# MCU_M4FSS0_ECC_AGGR_0_ECC_AGGR register map
Vendor: Texas Instruments
Peripheral module from a debugger description file (folder am243x).
Registers are 32-bit, access not given, reset 0x0 unless marked. A register's access mark holds for its fields unless they carry their own. Offsets are as the file gives them; lines under a group give offsets from that group; [hi:lo] are bit positions; {n}, {i} and the like mark numbered series; 'fields as' and 'values as' point back to an identical list; <NAME> marks a mode.

## MCU_M4FSS0_ECC_AGGR_0_ECC_AGGR
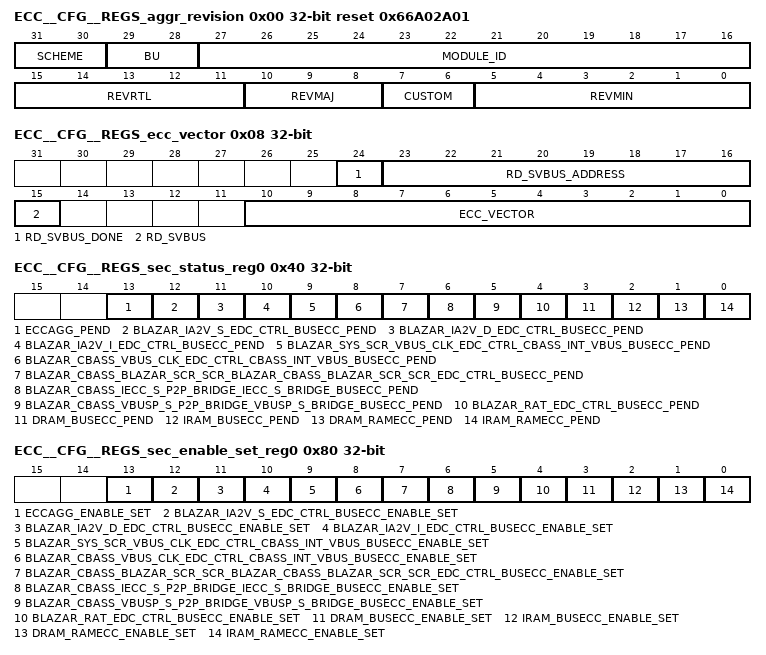
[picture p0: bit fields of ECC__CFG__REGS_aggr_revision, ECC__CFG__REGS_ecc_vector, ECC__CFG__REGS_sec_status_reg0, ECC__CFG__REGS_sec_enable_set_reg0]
0x00 ECC__CFG__REGS_aggr_revision ro reset 0x66A02A01 — Revision parameters
  [31:30] SCHEME
  [29:28] BU
  [27:16] MODULE_ID
  [15:11] REVRTL — RTL version
  [10:8] REVMAJ — Major version
  [7:6] CUSTOM — Custom version
  [5:0] REVMIN — Minor version
0x08 ECC__CFG__REGS_ecc_vector — ECC Vector Register
  [24] RD_SVBUS_DONE — Status to indicate if read on serial VBUS is complete, write of any value will clear this bit. (access R/W1TC)
  [23:16] RD_SVBUS_ADDRESS rw — Read address
  [15] RD_SVBUS — Write 1 to trigger a read on the serial VBUS (access R/W1TS)
  [10:0] ECC_VECTOR rw — Value written to select the corresponding ECC RAM for control or status
0x0C ECC__CFG__REGS_misc_status ro reset 0xE — Misc Status
  [10:0] NUM_RAMS — Indicates the number of RAMS serviced by the ECC aggregator
0x10 ECC__CFG__REGS_reserved_svbus rw — Reference other documents that contain the ECC RAM wrapper and EDC controller serial vbus register sets.
  [31:0] DATA — Serial VBUS register data
0x3C ECC__CFG__REGS_sec_eoi_reg — EOI Register
  [0] EOI_WR — EOI Register (access R/W1TS)
0x40 ECC__CFG__REGS_sec_status_reg0 — Interrupt Status Register 0
  [13] ECCAGG_PEND — Interrupt Pending Status for eccagg_pend (access R/W1TS)
  [12] BLAZAR_IA2V_S_EDC_CTRL_BUSECC_PEND — Interrupt Pending Status for blazar_Ia2v_s_edc_ctrl_busecc_pend (access R/W1TS)
  [11] BLAZAR_IA2V_D_EDC_CTRL_BUSECC_PEND — Interrupt Pending Status for blazar_Ia2v_d_edc_ctrl_busecc_pend (access R/W1TS)
  [10] BLAZAR_IA2V_I_EDC_CTRL_BUSECC_PEND — Interrupt Pending Status for blazar_Ia2v_i_edc_ctrl_busecc_pend (access R/W1TS)
  [9] BLAZAR_SYS_SCR_VBUS_CLK_EDC_CTRL_CBASS_INT_VBUS_BUSECC_PEND — Interrupt Pending Status for blazar_sys_scr_vbus_clk_edc_ctrl_cbass_int_vbus_busecc_pend (access R/W1TS)
  [8] BLAZAR_CBASS_VBUS_CLK_EDC_CTRL_CBASS_INT_VBUS_BUSECC_PEND — Interrupt Pending Status for blazar_cbass_vbus_clk_edc_ctrl_cbass_int_vbus_busecc_pend (access R/W1TS)
  [7] BLAZAR_CBASS_BLAZAR_SCR_SCR_BLAZAR_CBASS_BLAZAR_SCR_SCR_EDC_CTRL_BUSECC_PEND — Interrupt Pending Status for blazar_cbass_blazar_scr_scr_blazar_cbass_blazar_scr_scr_edc_ctrl_busecc_pend (access R/W1TS)
  [6] BLAZAR_CBASS_IECC_S_P2P_BRIDGE_IECC_S_BRIDGE_BUSECC_PEND — Interrupt Pending Status for blazar_cbass_Iecc_s_p2p_bridge_Iecc_s_bridge_busecc_pend (access R/W1TS)
  [5] BLAZAR_CBASS_VBUSP_S_P2P_BRIDGE_VBUSP_S_BRIDGE_BUSECC_PEND — Interrupt Pending Status for blazar_cbass_vbusp_s_p2p_bridge_vbusp_s_bridge_busecc_pend (access R/W1TS)
  [4] BLAZAR_RAT_EDC_CTRL_BUSECC_PEND — Interrupt Pending Status for blazar_rat_edc_ctrl_busecc_pend (access R/W1TS)
  [3] DRAM_BUSECC_PEND — Interrupt Pending Status for dram_busecc_pend (access R/W1TS)
  [2] IRAM_BUSECC_PEND — Interrupt Pending Status for iram_busecc_pend (access R/W1TS)
  [1] DRAM_RAMECC_PEND — Interrupt Pending Status for dram_ramecc_pend (access R/W1TS)
  [0] IRAM_RAMECC_PEND — Interrupt Pending Status for iram_ramecc_pend (access R/W1TS)
0x80 ECC__CFG__REGS_sec_enable_set_reg0 — Interrupt Enable Set Register 0
  [13] ECCAGG_ENABLE_SET — Interrupt Enable Set Register for eccagg_pend (access R/W1TS)
  [12] BLAZAR_IA2V_S_EDC_CTRL_BUSECC_ENABLE_SET — Interrupt Enable Set Register for blazar_Ia2v_s_edc_ctrl_busecc_pend (access R/W1TS)
  [11] BLAZAR_IA2V_D_EDC_CTRL_BUSECC_ENABLE_SET — Interrupt Enable Set Register for blazar_Ia2v_d_edc_ctrl_busecc_pend (access R/W1TS)
  [10] BLAZAR_IA2V_I_EDC_CTRL_BUSECC_ENABLE_SET — Interrupt Enable Set Register for blazar_Ia2v_i_edc_ctrl_busecc_pend (access R/W1TS)
  [9] BLAZAR_SYS_SCR_VBUS_CLK_EDC_CTRL_CBASS_INT_VBUS_BUSECC_ENABLE_SET — Interrupt Enable Set Register for blazar_sys_scr_vbus_clk_edc_ctrl_cbass_int_vbus_busecc_pend (access R/W1TS)
  [8] BLAZAR_CBASS_VBUS_CLK_EDC_CTRL_CBASS_INT_VBUS_BUSECC_ENABLE_SET — Interrupt Enable Set Register for blazar_cbass_vbus_clk_edc_ctrl_cbass_int_vbus_busecc_pend (access R/W1TS)
  [7] BLAZAR_CBASS_BLAZAR_SCR_SCR_BLAZAR_CBASS_BLAZAR_SCR_SCR_EDC_CTRL_BUSECC_ENABLE_SET — Interrupt Enable Set Register for blazar_cbass_blazar_scr_scr_blazar_cbass_blazar_scr_scr_edc_ctrl_busecc_pend (access R/W1TS)
  [6] BLAZAR_CBASS_IECC_S_P2P_BRIDGE_IECC_S_BRIDGE_BUSECC_ENABLE_SET — Interrupt Enable Set Register for blazar_cbass_Iecc_s_p2p_bridge_Iecc_s_bridge_busecc_pend (access R/W1TS)
  [5] BLAZAR_CBASS_VBUSP_S_P2P_BRIDGE_VBUSP_S_BRIDGE_BUSECC_ENABLE_SET — Interrupt Enable Set Register for blazar_cbass_vbusp_s_p2p_bridge_vbusp_s_bridge_busecc_pend (access R/W1TS)
  [4] BLAZAR_RAT_EDC_CTRL_BUSECC_ENABLE_SET — Interrupt Enable Set Register for blazar_rat_edc_ctrl_busecc_pend (access R/W1TS)
  [3] DRAM_BUSECC_ENABLE_SET — Interrupt Enable Set Register for dram_busecc_pend (access R/W1TS)
  [2] IRAM_BUSECC_ENABLE_SET — Interrupt Enable Set Register for iram_busecc_pend (access R/W1TS)
  [1] DRAM_RAMECC_ENABLE_SET — Interrupt Enable Set Register for dram_ramecc_pend (access R/W1TS)
  [0] IRAM_RAMECC_ENABLE_SET — Interrupt Enable Set Register for iram_ramecc_pend (access R/W1TS)
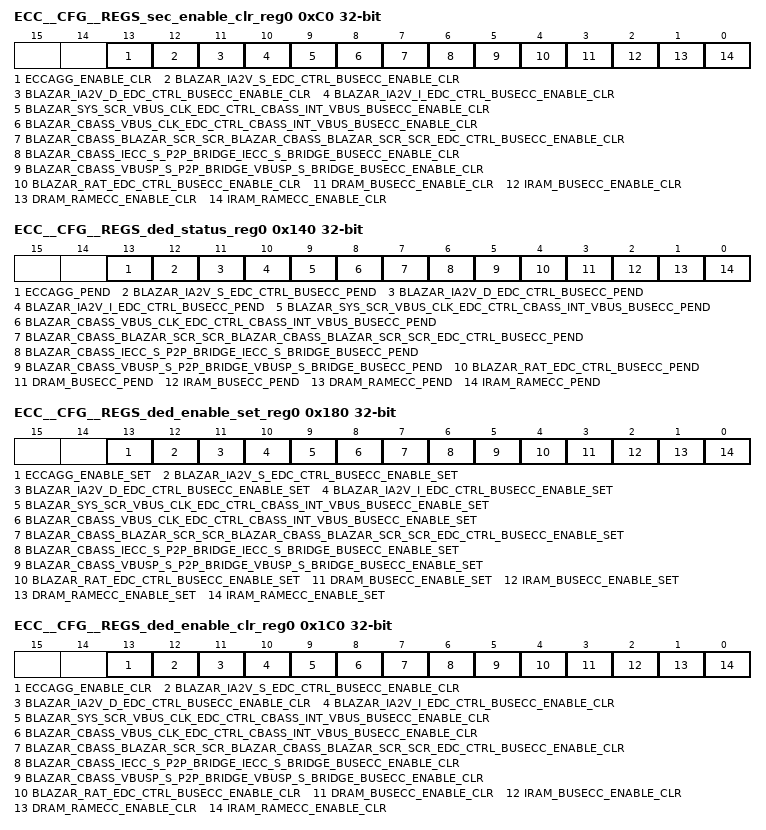
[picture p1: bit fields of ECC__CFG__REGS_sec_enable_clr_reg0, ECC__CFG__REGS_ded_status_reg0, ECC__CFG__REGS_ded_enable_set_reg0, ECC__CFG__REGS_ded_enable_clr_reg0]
0xC0 ECC__CFG__REGS_sec_enable_clr_reg0 — Interrupt Enable Clear Register 0
  [13] ECCAGG_ENABLE_CLR — Interrupt Enable Clear Register for eccagg_pend (access R/W1TC)
  [12] BLAZAR_IA2V_S_EDC_CTRL_BUSECC_ENABLE_CLR — Interrupt Enable Clear Register for blazar_Ia2v_s_edc_ctrl_busecc_pend (access R/W1TC)
  [11] BLAZAR_IA2V_D_EDC_CTRL_BUSECC_ENABLE_CLR — Interrupt Enable Clear Register for blazar_Ia2v_d_edc_ctrl_busecc_pend (access R/W1TC)
  [10] BLAZAR_IA2V_I_EDC_CTRL_BUSECC_ENABLE_CLR — Interrupt Enable Clear Register for blazar_Ia2v_i_edc_ctrl_busecc_pend (access R/W1TC)
  [9] BLAZAR_SYS_SCR_VBUS_CLK_EDC_CTRL_CBASS_INT_VBUS_BUSECC_ENABLE_CLR — Interrupt Enable Clear Register for blazar_sys_scr_vbus_clk_edc_ctrl_cbass_int_vbus_busecc_pend (access R/W1TC)
  [8] BLAZAR_CBASS_VBUS_CLK_EDC_CTRL_CBASS_INT_VBUS_BUSECC_ENABLE_CLR — Interrupt Enable Clear Register for blazar_cbass_vbus_clk_edc_ctrl_cbass_int_vbus_busecc_pend (access R/W1TC)
  [7] BLAZAR_CBASS_BLAZAR_SCR_SCR_BLAZAR_CBASS_BLAZAR_SCR_SCR_EDC_CTRL_BUSECC_ENABLE_CLR — Interrupt Enable Clear Register for blazar_cbass_blazar_scr_scr_blazar_cbass_blazar_scr_scr_edc_ctrl_busecc_pend (access R/W1TC)
  [6] BLAZAR_CBASS_IECC_S_P2P_BRIDGE_IECC_S_BRIDGE_BUSECC_ENABLE_CLR — Interrupt Enable Clear Register for blazar_cbass_Iecc_s_p2p_bridge_Iecc_s_bridge_busecc_pend (access R/W1TC)
  [5] BLAZAR_CBASS_VBUSP_S_P2P_BRIDGE_VBUSP_S_BRIDGE_BUSECC_ENABLE_CLR — Interrupt Enable Clear Register for blazar_cbass_vbusp_s_p2p_bridge_vbusp_s_bridge_busecc_pend (access R/W1TC)
  [4] BLAZAR_RAT_EDC_CTRL_BUSECC_ENABLE_CLR — Interrupt Enable Clear Register for blazar_rat_edc_ctrl_busecc_pend (access R/W1TC)
  [3] DRAM_BUSECC_ENABLE_CLR — Interrupt Enable Clear Register for dram_busecc_pend (access R/W1TC)
  [2] IRAM_BUSECC_ENABLE_CLR — Interrupt Enable Clear Register for iram_busecc_pend (access R/W1TC)
  [1] DRAM_RAMECC_ENABLE_CLR — Interrupt Enable Clear Register for dram_ramecc_pend (access R/W1TC)
  [0] IRAM_RAMECC_ENABLE_CLR — Interrupt Enable Clear Register for iram_ramecc_pend (access R/W1TC)
0x13C ECC__CFG__REGS_ded_eoi_reg — EOI Register
  [0] EOI_WR — EOI Register (access R/W1TS)
0x140 ECC__CFG__REGS_ded_status_reg0 — Interrupt Status Register 0
  fields as ECC__CFG__REGS_sec_status_reg0
0x180 ECC__CFG__REGS_ded_enable_set_reg0 — Interrupt Enable Set Register 0
  fields as ECC__CFG__REGS_sec_enable_set_reg0
0x1C0 ECC__CFG__REGS_ded_enable_clr_reg0 — Interrupt Enable Clear Register 0
  fields as ECC__CFG__REGS_sec_enable_clr_reg0
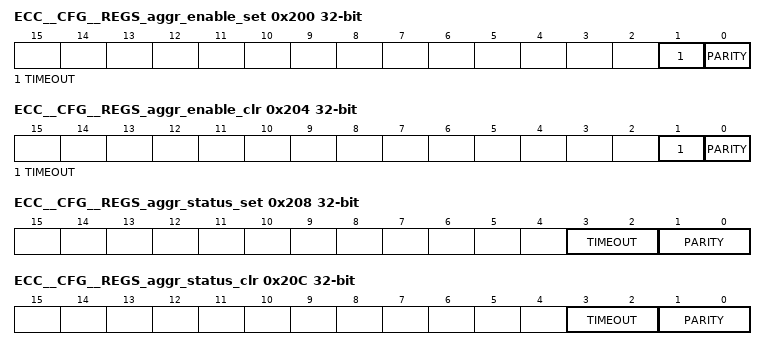
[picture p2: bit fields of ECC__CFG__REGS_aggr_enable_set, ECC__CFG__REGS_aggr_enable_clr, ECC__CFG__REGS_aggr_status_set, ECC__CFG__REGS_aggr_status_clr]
0x200 ECC__CFG__REGS_aggr_enable_set — AGGR interrupt enable set Register
  [1] TIMEOUT — interrupt enable set for svbus timeout errors (access R/W1TS)
  [0] PARITY — interrupt enable set for parity errors (access R/W1TS)
0x204 ECC__CFG__REGS_aggr_enable_clr — AGGR interrupt enable clear Register
  [1] TIMEOUT — interrupt enable clear for svbus timeout errors (access R/W1TC)
  [0] PARITY — interrupt enable clear for parity errors (access R/W1TC)
0x208 ECC__CFG__REGS_aggr_status_set — AGGR interrupt status set Register
  [3:2] TIMEOUT — interrupt status set for svbus timeout errors (access R/WI)
  [1:0] PARITY — interrupt status set for parity errors (access R/WI)
0x20C ECC__CFG__REGS_aggr_status_clr — AGGR interrupt status clear Register
  [3:2] TIMEOUT — interrupt status clear for svbus timeout errors (access R/WD)
  [1:0] PARITY — interrupt status clear for parity errors (access R/WD)
